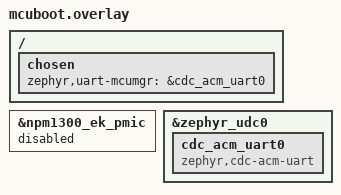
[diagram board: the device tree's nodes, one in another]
/ {
    chosen {
        zephyr,uart-mcumgr = &cdc_acm_uart0;
    };
};


&npm1300_ek_pmic {
    status = "disabled";
};

&zephyr_udc0 {
    cdc_acm_uart0: cdc_acm_uart0 {
        compatible = "zephyr,cdc-acm-uart";
    };
};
